# SYSCTRL_PADCONF_CORE register map
Vendor: Texas Instruments
Registers are 32-bit, access per field, reset 0x10F010F unless marked. A register's access mark holds for its fields unless they carry their own. Offsets are as the file gives them; [hi:lo] are bit positions; 'fields as' and 'values as' point back to an identical list.

## SYSCTRL_PADCONF_CORE (part 2 of 10)
0x00 CONTROL_PADCONF_CORE_REVISION ro reset not defined — Control module revision identifier Access conditions. Read: unrestricted, Write: unrestricted
  [31:0] REVISION — IP Revision
0x04 CONTROL_PADCONF_CORE_HWINFO ro reset 0x0 — Information about the IP module hardware configuration that is, typically the module HDL generics (if any). Access conditions. Read: unrestricted, Write: unrestricted
  [31:0] IP_HWINFO — IP-module dependent
0x10 CONTROL_PADCONF_CORE_SYSCONFIG reset 0x8 — Access conditions. Read: unrestricted, Write: unrestricted
  [3:2] IP_SYSCONFIG_IDLEMODE rw — Select the local clock-gating strategy0x2,0x3: Clock is automatically gated when there is no access to the Control Module through L4-interconnect .
    0=Clock is manually gated; 1=Clock is manually enabled
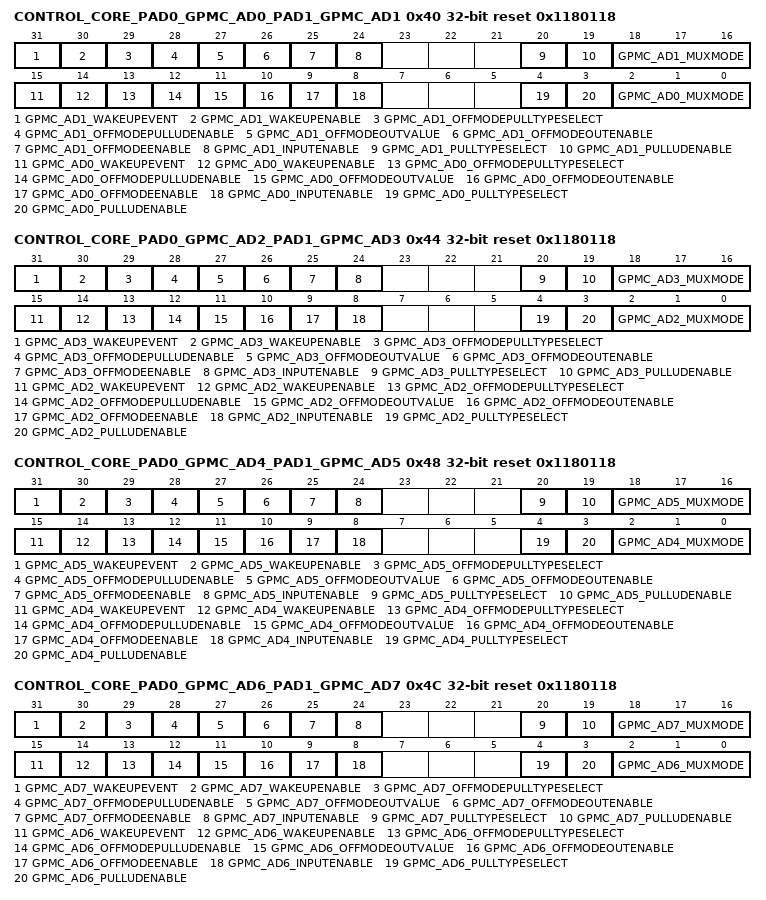
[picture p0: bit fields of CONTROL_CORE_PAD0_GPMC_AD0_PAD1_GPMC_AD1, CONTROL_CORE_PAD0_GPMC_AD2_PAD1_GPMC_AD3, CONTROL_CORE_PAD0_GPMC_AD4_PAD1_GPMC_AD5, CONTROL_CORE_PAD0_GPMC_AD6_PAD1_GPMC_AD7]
0x40 CONTROL_CORE_PAD0_GPMC_AD0_PAD1_GPMC_AD1 reset 0x1180118 — Register control for Pads gpmc_ad0 and gpmc_ad1 Access conditions. Read: unrestricted, Write: unrestricted
  [31] GPMC_AD1_WAKEUPEVENT ro — Pad_x wake-up event status latched in the I/O
    0=GPMC_AD1_WAKEUPEVENT_0_r (No wake-up event occurred); 1=GPMC_AD1_WAKEUPEVENT_1_r (A wake-up event occurred)
  [30] GPMC_AD1_WAKEUPENABLE rw — Input pad wake-up enable (and OFF mode input enable value)
    0=wake-up detection is disabled; 1=wake-up detection is enabled
  [29] GPMC_AD1_OFFMODEPULLTYPESELECT rw — OffMode mode pullup/down selection for pad gpmc_ad1
    0=Offmode pulldown selected; 1=Offmode pullup selected
  [28] GPMC_AD1_OFFMODEPULLUDENABLE rw — OffMode mode pullup/down enable for pad gpmc_ad1
    0=Offmode pullup/down disabled; 1=Offmode pullup/down enabled
  [27] GPMC_AD1_OFFMODEOUTVALUE rw — OffMode mode output value for pad gpmc_ad1
    0=Set value at 0; 1=Set value at 1
  [26] GPMC_AD1_OFFMODEOUTENABLE rw — OffMode mode output enable value for pad gpmc_ad1. This is an active low signal
    0=Output enable; 1=Output disable
  [25] GPMC_AD1_OFFMODEENABLE rw — OffMode mode override control for pad gpmc_ad1
    0=I/O state keeps its previous state when OFF mode is active; 1=I/O state is forced to OFF mode value when OFF mode is active
  [24] GPMC_AD1_INPUTENABLE rw — Input enable value for pad gpmc_ad1
    0=Input buffer of I/O cell is disabled; 1=Input buffer of I/O cell is enabled
  [20] GPMC_AD1_PULLTYPESELECT rw — pullup/down selection for pad gpmc_ad1
    0=pulldown selected; 1=pullup selected
  [19] GPMC_AD1_PULLUDENABLE rw — pullup/down enable for pad gpmc_ad1
    0=pullup/down disabled; 1=pullup/down enabled
  [18:16] GPMC_AD1_MUXMODE rw — Functional multiplexing selection for pad gpmc_ad1
    0=Select gpmc_ad1; 1=Select sdmmc2_dat1
  [15] GPMC_AD0_WAKEUPEVENT ro — Pad_x wake-up event status latched in the IO
    0=GPMC_AD0_WAKEUPEVENT_0_r (No wake-up event occurred); 1=GPMC_AD0_WAKEUPEVENT_1_r (A wake-up event occurred)
  [14] GPMC_AD0_WAKEUPENABLE rw — Input pad wake-up enable (and OFF mode input enable value)
    values as GPMC_AD1_WAKEUPENABLE
  [13] GPMC_AD0_OFFMODEPULLTYPESELECT rw — OffMode mode pullup/down selection for pad gpmc_ad0
    0=Offmode pulldown selected; 1=Offmode pullup selected
  [12] GPMC_AD0_OFFMODEPULLUDENABLE rw — OffMode mode pullup/down enable for pad gpmc_ad0
    values as GPMC_AD1_OFFMODEPULLUDENABLE
  [11] GPMC_AD0_OFFMODEOUTVALUE rw — OffMode mode output value for pad gpmc_ad0
    0=Set value at 0; 1=Set value at 1
  [10] GPMC_AD0_OFFMODEOUTENABLE rw — OffMode mode output enable value for pad gpmc_ad0. This is an active low signal
    0=Output enable; 1=Output disable
  [9] GPMC_AD0_OFFMODEENABLE rw — OffMode mode override control for pad gpmc_ad0
    values as GPMC_AD1_OFFMODEENABLE
  [8] GPMC_AD0_INPUTENABLE rw — Input enable value for pad gpmc_ad0
    values as GPMC_AD1_INPUTENABLE
  [4] GPMC_AD0_PULLTYPESELECT rw — pullup/down selection for pad gpmc_ad0
    0=pulldown selected; 1=pullup selected
  [3] GPMC_AD0_PULLUDENABLE rw — pullup/down enable for pad gpmc_ad0
    0=pullup/down disabled; 1=pullup/down enabled
  [2:0] GPMC_AD0_MUXMODE rw — Functional multiplexing selection for pad gpmc_ad0
    0=Select gpmc_ad0; 1=Select sdmmc2_dat0
0x44 CONTROL_CORE_PAD0_GPMC_AD2_PAD1_GPMC_AD3 reset 0x1180118 — Register control for Pads gpmc_ad2 and gpmc_ad3 Access conditions. Read: unrestricted, Write: unrestricted
  [31] GPMC_AD3_WAKEUPEVENT ro — Pad_x wake-up event status latched in the IO
    0=GPMC_AD3_WAKEUPEVENT_0_r (No wake-up event occurred); 1=GPMC_AD3_WAKEUPEVENT_1_r (A wake-up event occurred)
  [30] GPMC_AD3_WAKEUPENABLE rw — Input pad wake-up enable (and OFF mode input enable value)
    values as CONTROL_CORE_PAD0_GPMC_AD0_PAD1_GPMC_AD1.GPMC_AD1_WAKEUPENABLE
  [29] GPMC_AD3_OFFMODEPULLTYPESELECT rw — OffMode mode pullup/down selection for pad gpmc_ad3
    0=Offmode pulldown selected; 1=Offmode pullup selected
  [28] GPMC_AD3_OFFMODEPULLUDENABLE rw — OffMode mode pullup/down enable for pad gpmc_ad3
    values as CONTROL_CORE_PAD0_GPMC_AD0_PAD1_GPMC_AD1.GPMC_AD1_OFFMODEPULLUDENABLE
  [27] GPMC_AD3_OFFMODEOUTVALUE rw — OffMode mode output value for pad gpmc_ad3
    0=Set value at 0; 1=Set value at 1
  [26] GPMC_AD3_OFFMODEOUTENABLE rw — OffMode mode output enable value for pad gpmc_ad3. This is an active low signal
    0=Output enable; 1=Output disable
  [25] GPMC_AD3_OFFMODEENABLE rw — OffMode mode override control for pad gpmc_ad3
    values as CONTROL_CORE_PAD0_GPMC_AD0_PAD1_GPMC_AD1.GPMC_AD1_OFFMODEENABLE
  [24] GPMC_AD3_INPUTENABLE rw — Input enable value for pad gpmc_ad3
    values as CONTROL_CORE_PAD0_GPMC_AD0_PAD1_GPMC_AD1.GPMC_AD1_INPUTENABLE
  [20] GPMC_AD3_PULLTYPESELECT rw — pullup/down selection for pad gpmc_ad3
    0=pulldown selected; 1=pullup selected
  [19] GPMC_AD3_PULLUDENABLE rw — pullup/down enable for pad gpmc_ad3
    0=pullup/down disabled; 1=pullup/down enabled
  [18:16] GPMC_AD3_MUXMODE rw — Functional multiplexing selection for pad gpmc_ad3
    0=Select gpmc_ad3; 1=Select sdmmc2_dat3
  [15] GPMC_AD2_WAKEUPEVENT ro — Pad_x wake-up event status latched in the IO
    0=GPMC_AD2_WAKEUPEVENT_0_r (No wake-up event occurred); 1=GPMC_AD2_WAKEUPEVENT_1_r (A wake-up event occurred)
  [14] GPMC_AD2_WAKEUPENABLE rw — Input pad wake-up enable (and OFF mode input enable value)
    values as CONTROL_CORE_PAD0_GPMC_AD0_PAD1_GPMC_AD1.GPMC_AD1_WAKEUPENABLE
  [13] GPMC_AD2_OFFMODEPULLTYPESELECT rw — OffMode mode pullup/down selection for pad gpmc_ad2
    0=Offmode pulldown selected; 1=Offmode pullup selected
  [12] GPMC_AD2_OFFMODEPULLUDENABLE rw — OffMode mode pullup/down enable for pad gpmc_ad2
    values as CONTROL_CORE_PAD0_GPMC_AD0_PAD1_GPMC_AD1.GPMC_AD1_OFFMODEPULLUDENABLE
  [11] GPMC_AD2_OFFMODEOUTVALUE rw — OffMode mode output value for pad gpmc_ad2
    0=Set value at 0; 1=Set value at 1
  [10] GPMC_AD2_OFFMODEOUTENABLE rw — OffMode mode output enable value for pad gpmc_ad2. This is an active low signal
    0=Output enable; 1=Output disable
  [9] GPMC_AD2_OFFMODEENABLE rw — OffMode mode override control for pad gpmc_ad2
    values as CONTROL_CORE_PAD0_GPMC_AD0_PAD1_GPMC_AD1.GPMC_AD1_OFFMODEENABLE
  [8] GPMC_AD2_INPUTENABLE rw — Input enable value for pad gpmc_ad2
    values as CONTROL_CORE_PAD0_GPMC_AD0_PAD1_GPMC_AD1.GPMC_AD1_INPUTENABLE
  [4] GPMC_AD2_PULLTYPESELECT rw — pullup/down selection for pad gpmc_ad2
    0=pulldown selected; 1=pullup selected
  [3] GPMC_AD2_PULLUDENABLE rw — pullup/down enable for pad gpmc_ad2
    0=pullup/down disabled; 1=pullup/down enabled
  [2:0] GPMC_AD2_MUXMODE rw — Functional multiplexing selection for pad gpmc_ad2
    0=Select gpmc_ad2; 1=Select sdmmc2_dat2
0x48 CONTROL_CORE_PAD0_GPMC_AD4_PAD1_GPMC_AD5 reset 0x1180118 — Register control for Pads gpmc_ad4 and gpmc_ad5 Access conditions. Read: unrestricted, Write: unrestricted
  [31] GPMC_AD5_WAKEUPEVENT ro — Pad_x wake-up event status latched in the IO
    0=GPMC_AD5_WAKEUPEVENT_0_r (No wake-up event occurred); 1=GPMC_AD5_WAKEUPEVENT_1_r (A wake-up event occurred)
  [30] GPMC_AD5_WAKEUPENABLE rw — Input pad wake-up enable (and OFF mode input enable value)
    values as CONTROL_CORE_PAD0_GPMC_AD0_PAD1_GPMC_AD1.GPMC_AD1_WAKEUPENABLE
  [29] GPMC_AD5_OFFMODEPULLTYPESELECT rw — OffMode mode pullup/down selection for pad gpmc_ad5
    0=Offmode pulldown selected; 1=Offmode pullup selected
  [28] GPMC_AD5_OFFMODEPULLUDENABLE rw — OffMode mode pullup/down enable for pad gpmc_ad5
    values as CONTROL_CORE_PAD0_GPMC_AD0_PAD1_GPMC_AD1.GPMC_AD1_OFFMODEPULLUDENABLE
  [27] GPMC_AD5_OFFMODEOUTVALUE rw — OffMode mode output value for pad gpmc_ad5
    0=Set value at 0; 1=Set value at 1
  [26] GPMC_AD5_OFFMODEOUTENABLE rw — OffMode mode output enable value for pad gpmc_ad5. This is an active low signal
    0=Output enable; 1=Output disable
  [25] GPMC_AD5_OFFMODEENABLE rw — OffMode mode override control for pad gpmc_ad5
    values as CONTROL_CORE_PAD0_GPMC_AD0_PAD1_GPMC_AD1.GPMC_AD1_OFFMODEENABLE
  [24] GPMC_AD5_INPUTENABLE rw — Input enable value for pad gpmc_ad5
    values as CONTROL_CORE_PAD0_GPMC_AD0_PAD1_GPMC_AD1.GPMC_AD1_INPUTENABLE
  [20] GPMC_AD5_PULLTYPESELECT rw — pullup/down selection for pad gpmc_ad5
    0=pulldown selected; 1=pullup selected
  [19] GPMC_AD5_PULLUDENABLE rw — pullup/down enable for pad gpmc_ad5
    0=pullup/down disabled; 1=pullup/down enabled
  [18:16] GPMC_AD5_MUXMODE rw — Functional multiplexing selection for pad gpmc_ad5
    0=Select gpmc_ad5; 1=Select sdmmc2_dat5; 2=Select sdmmc2_dir_dat1
  [15] GPMC_AD4_WAKEUPEVENT ro — Pad_x wake-up event status latched in the IO
    0=GPMC_AD4_WAKEUPEVENT_0_r (No wake-up event occurred); 1=GPMC_AD4_WAKEUPEVENT_1_r (A wake-up event occurred)
  [14] GPMC_AD4_WAKEUPENABLE rw — Input pad wake-up enable (and OFF mode input enable value)
    values as CONTROL_CORE_PAD0_GPMC_AD0_PAD1_GPMC_AD1.GPMC_AD1_WAKEUPENABLE
  [13] GPMC_AD4_OFFMODEPULLTYPESELECT rw — OffMode mode pullup/down selection for pad gpmc_ad4
    0=Offmode pulldown selected; 1=Offmode pullup selected
  [12] GPMC_AD4_OFFMODEPULLUDENABLE rw — OffMode mode pullup/down enable for pad gpmc_ad4
    values as CONTROL_CORE_PAD0_GPMC_AD0_PAD1_GPMC_AD1.GPMC_AD1_OFFMODEPULLUDENABLE
  [11] GPMC_AD4_OFFMODEOUTVALUE rw — OffMode mode output value for pad gpmc_ad4
    0=Set value at 0; 1=Set value at 1
  [10] GPMC_AD4_OFFMODEOUTENABLE rw — OffMode mode output enable value for pad gpmc_ad4. This is an active low signal
    0=Output enable; 1=Output disable
  [9] GPMC_AD4_OFFMODEENABLE rw — OffMode mode override control for pad gpmc_ad4
    values as CONTROL_CORE_PAD0_GPMC_AD0_PAD1_GPMC_AD1.GPMC_AD1_OFFMODEENABLE
  [8] GPMC_AD4_INPUTENABLE rw — Input enable value for pad gpmc_ad4
    values as CONTROL_CORE_PAD0_GPMC_AD0_PAD1_GPMC_AD1.GPMC_AD1_INPUTENABLE
  [4] GPMC_AD4_PULLTYPESELECT rw — pullup/down selection for pad gpmc_ad4
    0=pulldown selected; 1=pullup selected
  [3] GPMC_AD4_PULLUDENABLE rw — pullup/down enable for pad gpmc_ad4
    0=pullup/down disabled; 1=pullup/down enabled
  [2:0] GPMC_AD4_MUXMODE rw — Functional multiplexing selection for pad gpmc_ad4
    0=Select gpmc_ad4; 1=Select sdmmc2_dat4; 2=Select sdmmc2_dir_dat0
0x4C CONTROL_CORE_PAD0_GPMC_AD6_PAD1_GPMC_AD7 reset 0x1180118 — Register control for Pads gpmc_ad6 and gpmc_ad7 Access conditions. Read: unrestricted, Write: unrestricted
  [31] GPMC_AD7_WAKEUPEVENT ro — Pad_x wake-up event status latched in the IO
    0=GPMC_AD7_WAKEUPEVENT_0_r (No wake-up event occurred); 1=GPMC_AD7_WAKEUPEVENT_1_r (A wake-up event occurred)
  [30] GPMC_AD7_WAKEUPENABLE rw — Input pad wake-up enable (and OFF mode input enable value)
    values as CONTROL_CORE_PAD0_GPMC_AD0_PAD1_GPMC_AD1.GPMC_AD1_WAKEUPENABLE
  [29] GPMC_AD7_OFFMODEPULLTYPESELECT rw — OffMode mode pullup/down selection for pad gpmc_ad7
    0=Offmode pulldown selected; 1=Offmode pullup selected
  [28] GPMC_AD7_OFFMODEPULLUDENABLE rw — OffMode mode pullup/down enable for pad gpmc_ad7
    values as CONTROL_CORE_PAD0_GPMC_AD0_PAD1_GPMC_AD1.GPMC_AD1_OFFMODEPULLUDENABLE
  [27] GPMC_AD7_OFFMODEOUTVALUE rw — OffMode mode output value for pad gpmc_ad7
    0=Set value at 0; 1=Set value at 1
  [26] GPMC_AD7_OFFMODEOUTENABLE rw — OffMode mode output enable value for pad gpmc_ad7. This is an active low signal
    0=Output enable; 1=Output disable
  [25] GPMC_AD7_OFFMODEENABLE rw — OffMode mode override control for pad gpmc_ad7
    values as CONTROL_CORE_PAD0_GPMC_AD0_PAD1_GPMC_AD1.GPMC_AD1_OFFMODEENABLE
  [24] GPMC_AD7_INPUTENABLE rw — Input enable value for pad gpmc_ad7
    values as CONTROL_CORE_PAD0_GPMC_AD0_PAD1_GPMC_AD1.GPMC_AD1_INPUTENABLE
  [20] GPMC_AD7_PULLTYPESELECT rw — pullup/down selection for pad gpmc_ad7
    0=pulldown selected; 1=pullup selected
  [19] GPMC_AD7_PULLUDENABLE rw — pullup/down enable for pad gpmc_ad7
    0=pullup/down disabled; 1=pullup/down enabled
  [18:16] GPMC_AD7_MUXMODE rw — Functional multiplexing selection for pad gpmc_ad7
    0=Select gpmc_ad7; 1=Select sdmmc2_dat7; 2=Select sdmmc2_clk_fdbk
  [15] GPMC_AD6_WAKEUPEVENT ro — Pad_x wake-up event status latched in the IO
    0=GPMC_AD6_WAKEUPEVENT_0_r (No wake-up event occurred); 1=GPMC_AD6_WAKEUPEVENT_1_r (A wake-up event occurred)
  [14] GPMC_AD6_WAKEUPENABLE rw — Input pad wake-up enable (and OFF mode input enable value)
    values as CONTROL_CORE_PAD0_GPMC_AD0_PAD1_GPMC_AD1.GPMC_AD1_WAKEUPENABLE
  [13] GPMC_AD6_OFFMODEPULLTYPESELECT rw — OffMode mode pullup/down selection for pad gpmc_ad6
    0=Offmode pulldown selected; 1=Offmode pullup selected
  [12] GPMC_AD6_OFFMODEPULLUDENABLE rw — OffMode mode pullup/down enable for pad gpmc_ad6
    values as CONTROL_CORE_PAD0_GPMC_AD0_PAD1_GPMC_AD1.GPMC_AD1_OFFMODEPULLUDENABLE
  [11] GPMC_AD6_OFFMODEOUTVALUE rw — OffMode mode output value for pad gpmc_ad6
    0=Set value at 0; 1=Set value at 1
  [10] GPMC_AD6_OFFMODEOUTENABLE rw — OffMode mode output enable value for pad gpmc_ad6. This is an active low signal
    0=Output enable; 1=Output disable
  [9] GPMC_AD6_OFFMODEENABLE rw — OffMode mode override control for pad gpmc_ad6
    values as CONTROL_CORE_PAD0_GPMC_AD0_PAD1_GPMC_AD1.GPMC_AD1_OFFMODEENABLE
  [8] GPMC_AD6_INPUTENABLE rw — Input enable value for pad gpmc_ad6
    values as CONTROL_CORE_PAD0_GPMC_AD0_PAD1_GPMC_AD1.GPMC_AD1_INPUTENABLE
  [4] GPMC_AD6_PULLTYPESELECT rw — pullup/down selection for pad gpmc_ad6
    0=pulldown selected; 1=pullup selected
  [3] GPMC_AD6_PULLUDENABLE rw — pullup/down enable for pad gpmc_ad6
    0=pullup/down disabled; 1=pullup/down enabled
  [2:0] GPMC_AD6_MUXMODE rw — Functional multiplexing selection for pad gpmc_ad6
    0=Select gpmc_ad6; 1=Select sdmmc2_dat6; 2=Select sdmmc2_dir_cmd
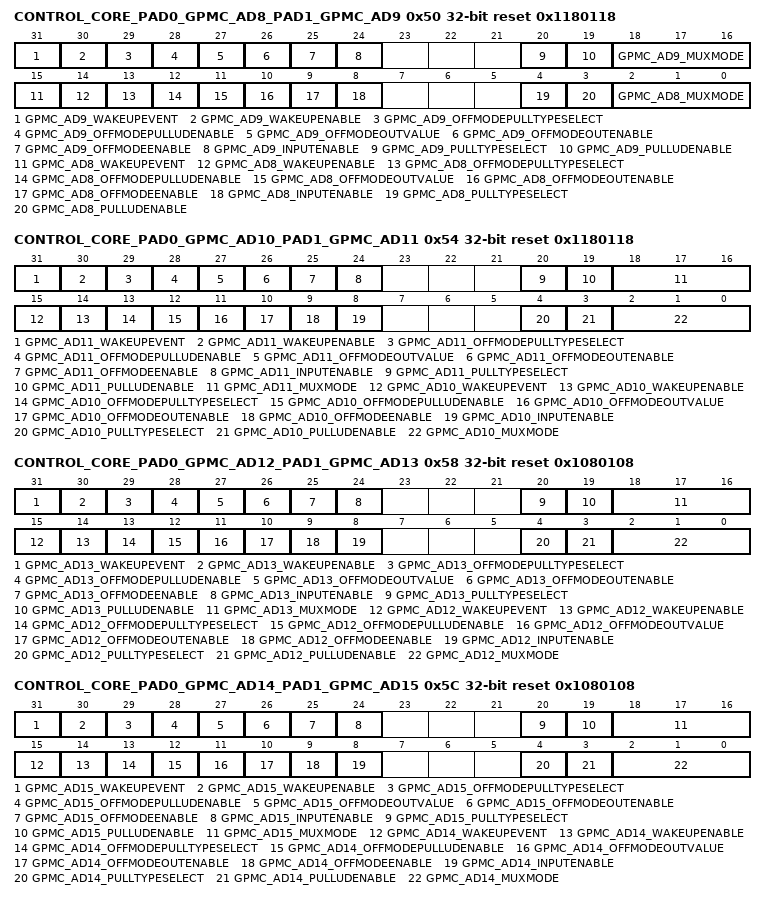
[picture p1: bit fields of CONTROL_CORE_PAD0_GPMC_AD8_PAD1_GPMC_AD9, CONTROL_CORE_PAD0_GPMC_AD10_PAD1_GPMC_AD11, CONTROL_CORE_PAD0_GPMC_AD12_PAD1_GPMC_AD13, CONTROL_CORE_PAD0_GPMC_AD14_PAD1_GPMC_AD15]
0x50 CONTROL_CORE_PAD0_GPMC_AD8_PAD1_GPMC_AD9 reset 0x1180118 — Register control for Pads gpmc_ad8 and gpmc_ad9 Access conditions. Read: unrestricted, Write: unrestricted
  [31] GPMC_AD9_WAKEUPEVENT ro — Pad_x wake-up event status latched in the IO
    0=GPMC_AD9_WAKEUPEVENT_0_r (No wake-up event occurred); 1=GPMC_AD9_WAKEUPEVENT_1_r (A wake-up event occurred)
  [30] GPMC_AD9_WAKEUPENABLE rw — Input pad wake-up enable (and OFF mode input enable value)
    values as CONTROL_CORE_PAD0_GPMC_AD0_PAD1_GPMC_AD1.GPMC_AD1_WAKEUPENABLE
  [29] GPMC_AD9_OFFMODEPULLTYPESELECT rw — OffMode mode pullup/down selection for pad gpmc_ad9
    0=Offmode pulldown selected; 1=Offmode pullup selected
  [28] GPMC_AD9_OFFMODEPULLUDENABLE rw — OffMode mode pullup/down enable for pad gpmc_ad9
    values as CONTROL_CORE_PAD0_GPMC_AD0_PAD1_GPMC_AD1.GPMC_AD1_OFFMODEPULLUDENABLE
  [27] GPMC_AD9_OFFMODEOUTVALUE rw — OffMode mode output value for pad gpmc_ad9
    0=Set value at 0; 1=Set value at 1
  [26] GPMC_AD9_OFFMODEOUTENABLE rw — OffMode mode output enable value for pad gpmc_ad9. This is an active low signal
    0=Output enable; 1=Output disable
  [25] GPMC_AD9_OFFMODEENABLE rw — OffMode mode override control for pad gpmc_ad9
    values as CONTROL_CORE_PAD0_GPMC_AD0_PAD1_GPMC_AD1.GPMC_AD1_OFFMODEENABLE
  [24] GPMC_AD9_INPUTENABLE rw — Input enable value for pad gpmc_ad9
    values as CONTROL_CORE_PAD0_GPMC_AD0_PAD1_GPMC_AD1.GPMC_AD1_INPUTENABLE
  [20] GPMC_AD9_PULLTYPESELECT rw — pullup/down selection for pad gpmc_ad9
    0=pulldown selected; 1=pullup selected
  [19] GPMC_AD9_PULLUDENABLE rw — pullup/down enable for pad gpmc_ad9
    0=pullup/down disabled; 1=pullup/down enabled
  [18:16] GPMC_AD9_MUXMODE rw — Functional multiplexing selection for pad gpmc_ad9
    0=Select gpmc_ad9; 1=Select kpd_row1; 2=Select c2c_data14; 3=Select gpio_33; 5=Select sdmmc1_dat1
  [15] GPMC_AD8_WAKEUPEVENT ro — Pad_x wake-up event status latched in the IO
    0=GPMC_AD8_WAKEUPEVENT_0_r (No wake-up event occurred); 1=GPMC_AD8_WAKEUPEVENT_1_r (A wake-up event occurred)
  [14] GPMC_AD8_WAKEUPENABLE rw — Input pad wake-up enable (and OFF mode input enable value)
    values as CONTROL_CORE_PAD0_GPMC_AD0_PAD1_GPMC_AD1.GPMC_AD1_WAKEUPENABLE
  [13] GPMC_AD8_OFFMODEPULLTYPESELECT rw — OffMode mode pullup/down selection for pad gpmc_ad8
    0=Offmode pulldown selected; 1=Offmode pullup selected
  [12] GPMC_AD8_OFFMODEPULLUDENABLE rw — OffMode mode pullup/down enable for pad gpmc_ad8
    values as CONTROL_CORE_PAD0_GPMC_AD0_PAD1_GPMC_AD1.GPMC_AD1_OFFMODEPULLUDENABLE
  [11] GPMC_AD8_OFFMODEOUTVALUE rw — OffMode mode output value for pad gpmc_ad8
    0=Set value at 0; 1=Set value at 1
  [10] GPMC_AD8_OFFMODEOUTENABLE rw — OffMode mode output enable value for pad gpmc_ad8. This is an active low signal
    0=Output enable; 1=Output disable
  [9] GPMC_AD8_OFFMODEENABLE rw — OffMode mode override control for pad gpmc_ad8
    values as CONTROL_CORE_PAD0_GPMC_AD0_PAD1_GPMC_AD1.GPMC_AD1_OFFMODEENABLE
  [8] GPMC_AD8_INPUTENABLE rw — Input enable value for pad gpmc_ad8
    values as CONTROL_CORE_PAD0_GPMC_AD0_PAD1_GPMC_AD1.GPMC_AD1_INPUTENABLE
  [4] GPMC_AD8_PULLTYPESELECT rw — pullup/down selection for pad gpmc_ad8
    0=pulldown selected; 1=pullup selected
  [3] GPMC_AD8_PULLUDENABLE rw — pullup/down enable for pad gpmc_ad8
    0=pullup/down disabled; 1=pullup/down enabled
  [2:0] GPMC_AD8_MUXMODE rw — Functional multiplexing selection for pad gpmc_ad8
    0=Select gpmc_ad8; 1=Select kpd_row0; 2=Select c2c_data15; 3=Select gpio_32; 5=Select sdmmc1_dat0
0x54 CONTROL_CORE_PAD0_GPMC_AD10_PAD1_GPMC_AD11 reset 0x1180118 — Register control for Pads gpmc_ad10 and gpmc_ad11 Access conditions. Read: unrestricted, Write: unrestricted
  [31] GPMC_AD11_WAKEUPEVENT ro — Pad_x wake-up event status latched in the IO
    0=GPMC_AD11_WAKEUPEVENT_0_r (No wake-up event occurred); 1=GPMC_AD11_WAKEUPEVENT_1_r (A wake-up event occurred)
  [30] GPMC_AD11_WAKEUPENABLE rw — Input pad wake-up enable (and OFF mode input enable value)
    values as CONTROL_CORE_PAD0_GPMC_AD0_PAD1_GPMC_AD1.GPMC_AD1_WAKEUPENABLE
  [29] GPMC_AD11_OFFMODEPULLTYPESELECT rw — OffMode mode pullup/down selection for pad gpmc_ad11
    0=Offmode pulldown selected; 1=Offmode pullup selected
  [28] GPMC_AD11_OFFMODEPULLUDENABLE rw — OffMode mode pullup/down enable for pad gpmc_ad11
    values as CONTROL_CORE_PAD0_GPMC_AD0_PAD1_GPMC_AD1.GPMC_AD1_OFFMODEPULLUDENABLE
  [27] GPMC_AD11_OFFMODEOUTVALUE rw — OffMode mode output value for pad gpmc_ad11
    0=Set value at 0; 1=Set value at 1
  [26] GPMC_AD11_OFFMODEOUTENABLE rw — OffMode mode output enable value for pad gpmc_ad11. This is an active low signal
    0=Output enable; 1=Output disable
  [25] GPMC_AD11_OFFMODEENABLE rw — OffMode mode override control for pad gpmc_ad11
    values as CONTROL_CORE_PAD0_GPMC_AD0_PAD1_GPMC_AD1.GPMC_AD1_OFFMODEENABLE
  [24] GPMC_AD11_INPUTENABLE rw — Input enable value for pad gpmc_ad11
    values as CONTROL_CORE_PAD0_GPMC_AD0_PAD1_GPMC_AD1.GPMC_AD1_INPUTENABLE
  [20] GPMC_AD11_PULLTYPESELECT rw — pullup/down selection for pad gpmc_ad11
    0=pulldown selected; 1=pullup selected
  [19] GPMC_AD11_PULLUDENABLE rw — pullup/down enable for pad gpmc_ad11
    0=pullup/down disabled; 1=pullup/down enabled
  [18:16] GPMC_AD11_MUXMODE rw — Functional multiplexing selection for pad gpmc_ad11
    0=Select gpmc_ad11; 1=Select kpd_row3; 2=Select c2c_data12; 3=Select gpio_35; 5=Select sdmmc1_dat3
  [15] GPMC_AD10_WAKEUPEVENT ro — Pad_x wake-up event status latched in the IO
    0=GPMC_AD10_WAKEUPEVENT_0_r (No wake-up event occurred); 1=GPMC_AD10_WAKEUPEVENT_1_r (A wake-up event occurred)
  [14] GPMC_AD10_WAKEUPENABLE rw — Input pad wake-up enable (and OFF mode input enable value)
    values as CONTROL_CORE_PAD0_GPMC_AD0_PAD1_GPMC_AD1.GPMC_AD1_WAKEUPENABLE
  [13] GPMC_AD10_OFFMODEPULLTYPESELECT rw — OffMode mode pullup/down selection for pad gpmc_ad10
    0=Offmode pulldown selected; 1=Offmode pullup selected
  [12] GPMC_AD10_OFFMODEPULLUDENABLE rw — OffMode mode pullup/down enable for pad gpmc_ad10
    values as CONTROL_CORE_PAD0_GPMC_AD0_PAD1_GPMC_AD1.GPMC_AD1_OFFMODEPULLUDENABLE
  [11] GPMC_AD10_OFFMODEOUTVALUE rw — OffMode mode output value for pad gpmc_ad10
    0=Set value at 0; 1=Set value at 1
  [10] GPMC_AD10_OFFMODEOUTENABLE rw — OffMode mode output enable value for pad gpmc_ad10. This is an active low signal
    0=Output enable; 1=Output disable
  [9] GPMC_AD10_OFFMODEENABLE rw — OffMode mode override control for pad gpmc_ad10
    values as CONTROL_CORE_PAD0_GPMC_AD0_PAD1_GPMC_AD1.GPMC_AD1_OFFMODEENABLE
  [8] GPMC_AD10_INPUTENABLE rw — Input enable value for pad gpmc_ad10
    values as CONTROL_CORE_PAD0_GPMC_AD0_PAD1_GPMC_AD1.GPMC_AD1_INPUTENABLE
  [4] GPMC_AD10_PULLTYPESELECT rw — pullup/down selection for pad gpmc_ad10
    0=pulldown selected; 1=pullup selected
  [3] GPMC_AD10_PULLUDENABLE rw — pullup/down enable for pad gpmc_ad10
    0=pullup/down disabled; 1=pullup/down enabled
  [2:0] GPMC_AD10_MUXMODE rw — Functional multiplexing selection for pad gpmc_ad10
    0=Select gpmc_ad10; 1=Select kpd_row2; 2=Select c2c_data13; 3=Select gpio_34; 5=Select sdmmc1_dat2
0x58 CONTROL_CORE_PAD0_GPMC_AD12_PAD1_GPMC_AD13 reset 0x1080108 — Register control for Pads gpmc_ad12 and gpmc_ad13 Access conditions. Read: unrestricted, Write: unrestricted
  [31] GPMC_AD13_WAKEUPEVENT ro — Pad_x wake-up event status latched in the IO
    0=GPMC_AD13_WAKEUPEVENT_0_r (No wake-up event occurred); 1=GPMC_AD13_WAKEUPEVENT_1_r (A wake-up event occurred)
  [30] GPMC_AD13_WAKEUPENABLE rw — Input pad wake-up enable (and OFF mode input enable value)
    values as CONTROL_CORE_PAD0_GPMC_AD0_PAD1_GPMC_AD1.GPMC_AD1_WAKEUPENABLE
  [29] GPMC_AD13_OFFMODEPULLTYPESELECT rw — OffMode mode pullup/down selection for pad gpmc_ad13
    0=Offmode pulldown selected; 1=Offmode pullup selected
  [28] GPMC_AD13_OFFMODEPULLUDENABLE rw — OffMode mode pullup/down enable for pad gpmc_ad13
    values as CONTROL_CORE_PAD0_GPMC_AD0_PAD1_GPMC_AD1.GPMC_AD1_OFFMODEPULLUDENABLE
  [27] GPMC_AD13_OFFMODEOUTVALUE rw — OffMode mode output value for pad gpmc_ad13
    0=Set value at 0; 1=Set value at 1
  [26] GPMC_AD13_OFFMODEOUTENABLE rw — OffMode mode output enable value for pad gpmc_ad13. This is an active low signal
    0=Output enable; 1=Output disable
  [25] GPMC_AD13_OFFMODEENABLE rw — OffMode mode override control for pad gpmc_ad13
    values as CONTROL_CORE_PAD0_GPMC_AD0_PAD1_GPMC_AD1.GPMC_AD1_OFFMODEENABLE
  [24] GPMC_AD13_INPUTENABLE rw — Input enable value for pad gpmc_ad13
    values as CONTROL_CORE_PAD0_GPMC_AD0_PAD1_GPMC_AD1.GPMC_AD1_INPUTENABLE
  [20] GPMC_AD13_PULLTYPESELECT rw — pullup/down selection for pad gpmc_ad13
    0=pulldown selected; 1=pullup selected
  [19] GPMC_AD13_PULLUDENABLE rw — pullup/down enable for pad gpmc_ad13
    0=pullup/down disabled; 1=pullup/down enabled
  [18:16] GPMC_AD13_MUXMODE rw — Functional multiplexing selection for pad gpmc_ad13
    0=Select gpmc_ad13; 1=Select kpd_col1; 2=Select c2c_data10; 3=Select gpio_37; 5=Select sdmmc1_dat5
  [15] GPMC_AD12_WAKEUPEVENT ro — Pad_x wake-up event status latched in the IO
    0=GPMC_AD12_WAKEUPEVENT_0_r (No wake-up event occurred); 1=GPMC_AD12_WAKEUPEVENT_1_r (A wake-up event occurred)
  [14] GPMC_AD12_WAKEUPENABLE rw — Input pad wake-up enable (and OFF mode input enable value)
    values as CONTROL_CORE_PAD0_GPMC_AD0_PAD1_GPMC_AD1.GPMC_AD1_WAKEUPENABLE
  [13] GPMC_AD12_OFFMODEPULLTYPESELECT rw — OffMode mode pullup/down selection for pad gpmc_ad12
    0=Offmode pulldown selected; 1=Offmode pullup selected
  [12] GPMC_AD12_OFFMODEPULLUDENABLE rw — OffMode mode pullup/down enable for pad gpmc_ad12
    values as CONTROL_CORE_PAD0_GPMC_AD0_PAD1_GPMC_AD1.GPMC_AD1_OFFMODEPULLUDENABLE
  [11] GPMC_AD12_OFFMODEOUTVALUE rw — OffMode mode output value for pad gpmc_ad12
    0=Set value at 0; 1=Set value at 1
  [10] GPMC_AD12_OFFMODEOUTENABLE rw — OffMode mode output enable value for pad gpmc_ad12. This is an active low signal
    0=Output enable; 1=Output disable
  [9] GPMC_AD12_OFFMODEENABLE rw — OffMode mode override control for pad gpmc_ad12
    values as CONTROL_CORE_PAD0_GPMC_AD0_PAD1_GPMC_AD1.GPMC_AD1_OFFMODEENABLE
  [8] GPMC_AD12_INPUTENABLE rw — Input enable value for pad gpmc_ad12
    values as CONTROL_CORE_PAD0_GPMC_AD0_PAD1_GPMC_AD1.GPMC_AD1_INPUTENABLE
  [4] GPMC_AD12_PULLTYPESELECT rw — pullup/down selection for pad gpmc_ad12
    0=pulldown selected; 1=pullup selected
  [3] GPMC_AD12_PULLUDENABLE rw — pullup/down enable for pad gpmc_ad12
    0=pullup/down disabled; 1=pullup/down enabled
  [2:0] GPMC_AD12_MUXMODE rw — Functional multiplexing selection for pad gpmc_ad12
    0=Select gpmc_ad12; 1=Select kpd_col0; 2=Select c2c_data11; 3=Select gpio_36; 5=Select sdmmc1_dat4
0x5C CONTROL_CORE_PAD0_GPMC_AD14_PAD1_GPMC_AD15 reset 0x1080108 — Register control for Pads gpmc_ad14 and gpmc_ad15 Access conditions. Read: unrestricted, Write: unrestricted
  [31] GPMC_AD15_WAKEUPEVENT ro — Pad_x wake-up event status latched in the IO
    0=GPMC_AD15_WAKEUPEVENT_0_r (No wake-up event occurred); 1=GPMC_AD15_WAKEUPEVENT_1_r (A wake-up event occurred)
  [30] GPMC_AD15_WAKEUPENABLE rw — Input pad wake-up enable (and OFF mode input enable value)
    values as CONTROL_CORE_PAD0_GPMC_AD0_PAD1_GPMC_AD1.GPMC_AD1_WAKEUPENABLE
  [29] GPMC_AD15_OFFMODEPULLTYPESELECT rw — OffMode mode pullup/down selection for pad gpmc_ad15
    0=Offmode pulldown selected; 1=Offmode pullup selected
  [28] GPMC_AD15_OFFMODEPULLUDENABLE rw — OffMode mode pullup/down enable for pad gpmc_ad15
    values as CONTROL_CORE_PAD0_GPMC_AD0_PAD1_GPMC_AD1.GPMC_AD1_OFFMODEPULLUDENABLE
  [27] GPMC_AD15_OFFMODEOUTVALUE rw — OffMode mode output value for pad gpmc_ad15
    0=Set value at 0; 1=Set value at 1
  [26] GPMC_AD15_OFFMODEOUTENABLE rw — OffMode mode output enable value for pad gpmc_ad15. This is an active low signal
    0=Output enable; 1=Output disable
  [25] GPMC_AD15_OFFMODEENABLE rw — OffMode mode override control for pad gpmc_ad15
    values as CONTROL_CORE_PAD0_GPMC_AD0_PAD1_GPMC_AD1.GPMC_AD1_OFFMODEENABLE
  [24] GPMC_AD15_INPUTENABLE rw — Input enable value for pad gpmc_ad15
    values as CONTROL_CORE_PAD0_GPMC_AD0_PAD1_GPMC_AD1.GPMC_AD1_INPUTENABLE
  [20] GPMC_AD15_PULLTYPESELECT rw — pullup/down selection for pad gpmc_ad15
    0=pulldown selected; 1=pullup selected
  [19] GPMC_AD15_PULLUDENABLE rw — pullup/down enable for pad gpmc_ad15
    0=pullup/down disabled; 1=pullup/down enabled
  [18:16] GPMC_AD15_MUXMODE rw — Functional multiplexing selection for pad gpmc_ad15
    0=Select gpmc_ad15; 1=Select kpd_col3; 2=Select c2c_data8; 3=Select gpio_39; 5=Select sdmmc1_dat7
  [15] GPMC_AD14_WAKEUPEVENT ro — Pad_x wake-up event status latched in the IO
    0=GPMC_AD14_WAKEUPEVENT_0_r (No wake-up event occurred); 1=GPMC_AD14_WAKEUPEVENT_1_r (A wake-up event occurred)
  [14] GPMC_AD14_WAKEUPENABLE rw — Input pad wake-up enable (and OFF mode input enable value)
    values as CONTROL_CORE_PAD0_GPMC_AD0_PAD1_GPMC_AD1.GPMC_AD1_WAKEUPENABLE
  [13] GPMC_AD14_OFFMODEPULLTYPESELECT rw — OffMode mode pullup/down selection for pad gpmc_ad14
    0=Offmode pulldown selected; 1=Offmode pullup selected
  [12] GPMC_AD14_OFFMODEPULLUDENABLE rw — OffMode mode pullup/down enable for pad gpmc_ad14
    values as CONTROL_CORE_PAD0_GPMC_AD0_PAD1_GPMC_AD1.GPMC_AD1_OFFMODEPULLUDENABLE
  [11] GPMC_AD14_OFFMODEOUTVALUE rw — OffMode mode output value for pad gpmc_ad14
    0=Set value at 0; 1=Set value at 1
  [10] GPMC_AD14_OFFMODEOUTENABLE rw — OffMode mode output enable value for pad gpmc_ad14. This is an active low signal
    0=Output enable; 1=Output disable
  [9] GPMC_AD14_OFFMODEENABLE rw — OffMode mode override control for pad gpmc_ad14
    values as CONTROL_CORE_PAD0_GPMC_AD0_PAD1_GPMC_AD1.GPMC_AD1_OFFMODEENABLE
  [8] GPMC_AD14_INPUTENABLE rw — Input enable value for pad gpmc_ad14
    values as CONTROL_CORE_PAD0_GPMC_AD0_PAD1_GPMC_AD1.GPMC_AD1_INPUTENABLE
  [4] GPMC_AD14_PULLTYPESELECT rw — pullup/down selection for pad gpmc_ad14
    0=pulldown selected; 1=pullup selected
  [3] GPMC_AD14_PULLUDENABLE rw — pullup/down enable for pad gpmc_ad14
    0=pullup/down disabled; 1=pullup/down enabled
  [2:0] GPMC_AD14_MUXMODE rw — Functional multiplexing selection for pad gpmc_ad14
    0=Select gpmc_ad14; 1=Select kpd_col2; 2=Select c2c_data9; 3=Select gpio_38; 5=Select sdmmc1_dat6
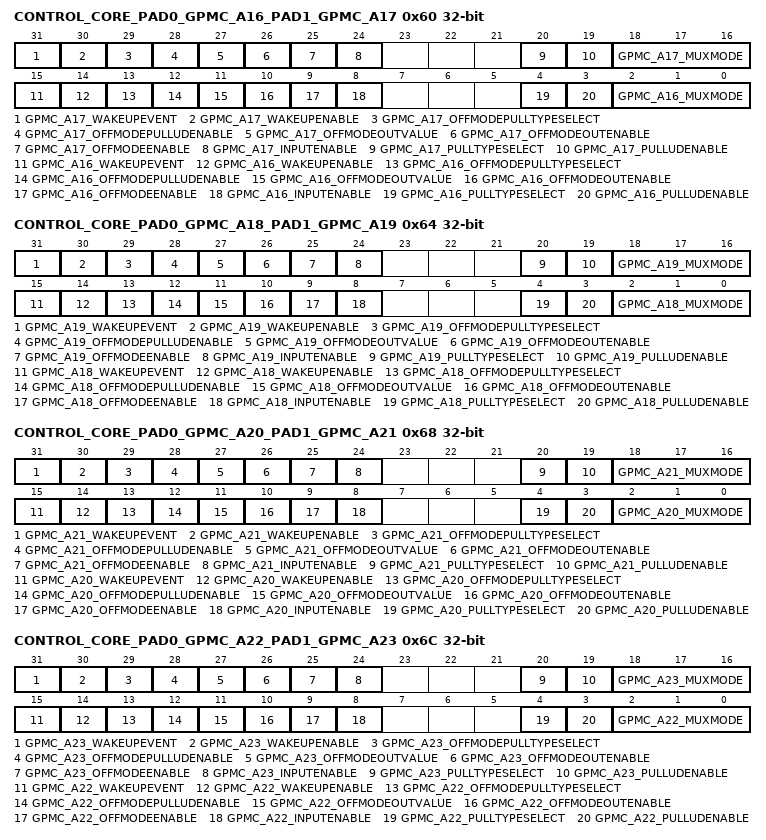
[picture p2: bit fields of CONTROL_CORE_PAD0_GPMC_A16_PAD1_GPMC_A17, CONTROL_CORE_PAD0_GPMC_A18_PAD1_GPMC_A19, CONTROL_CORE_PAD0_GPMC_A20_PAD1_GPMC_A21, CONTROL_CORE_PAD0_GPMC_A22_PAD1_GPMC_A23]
0x60 CONTROL_CORE_PAD0_GPMC_A16_PAD1_GPMC_A17 — Register control for Pads gpmc_a16 and gpmc_a17 Access conditions. Read: unrestricted, Write: unrestricted
  [31] GPMC_A17_WAKEUPEVENT ro — Pad_x wake-up event status latched in the IO
    0=GPMC_A17_WAKEUPEVENT_0_r (No wake-up event occurred); 1=GPMC_A17_WAKEUPEVENT_1_r (A wake-up event occurred)
  [30] GPMC_A17_WAKEUPENABLE rw — Input pad wake-up enable (and OFF mode input enable value)
    values as CONTROL_CORE_PAD0_GPMC_AD0_PAD1_GPMC_AD1.GPMC_AD1_WAKEUPENABLE
  [29] GPMC_A17_OFFMODEPULLTYPESELECT rw — OffMode mode pullup/down selection for pad gpmc_a17
    0=Offmode pulldown selected; 1=Offmode pullup selected
  [28] GPMC_A17_OFFMODEPULLUDENABLE rw — OffMode mode pullup/down enable for pad gpmc_a17
    values as CONTROL_CORE_PAD0_GPMC_AD0_PAD1_GPMC_AD1.GPMC_AD1_OFFMODEPULLUDENABLE
  [27] GPMC_A17_OFFMODEOUTVALUE rw — OffMode mode output value for pad gpmc_a17
    0=Set value at 0; 1=Set value at 1
  [26] GPMC_A17_OFFMODEOUTENABLE rw — OffMode mode output enable value for pad gpmc_a17. This is an active low signal
    0=Output enable; 1=Output disable
  [25] GPMC_A17_OFFMODEENABLE rw — OffMode mode override control for pad gpmc_a17
    values as CONTROL_CORE_PAD0_GPMC_AD0_PAD1_GPMC_AD1.GPMC_AD1_OFFMODEENABLE
  [24] GPMC_A17_INPUTENABLE rw — Input enable value for pad gpmc_a17
    values as CONTROL_CORE_PAD0_GPMC_AD0_PAD1_GPMC_AD1.GPMC_AD1_INPUTENABLE
  [20] GPMC_A17_PULLTYPESELECT rw — pullup/down selection for pad gpmc_a17
    0=pulldown selected; 1=pullup selected
  [19] GPMC_A17_PULLUDENABLE rw — pullup/down enable for pad gpmc_a17
    0=pullup/down disabled; 1=pullup/down enabled
  [18:16] GPMC_A17_MUXMODE rw — Functional multiplexing selection for pad gpmc_a17
    0=Select gpmc_a17; 1=Select kpd_row5; 2=Select c2c_datain1; 3=Select gpio_41; 4=Select venc_656_data1; 7=Select safe_mode
  [15] GPMC_A16_WAKEUPEVENT ro — Pad_x wake-up event status latched in the IO
    0=GPMC_A16_WAKEUPEVENT_0_r (No wake-up event occurred); 1=GPMC_A16_WAKEUPEVENT_1_r (A wake-up event occurred)
  [14] GPMC_A16_WAKEUPENABLE rw — Input pad wake-up enable (and OFF mode input enable value)
    values as CONTROL_CORE_PAD0_GPMC_AD0_PAD1_GPMC_AD1.GPMC_AD1_WAKEUPENABLE
  [13] GPMC_A16_OFFMODEPULLTYPESELECT rw — OffMode mode pullup/down selection for pad gpmc_a16
    0=Offmode pulldown selected; 1=Offmode pullup selected
  [12] GPMC_A16_OFFMODEPULLUDENABLE rw — OffMode mode pullup/down enable for pad gpmc_a16
    values as CONTROL_CORE_PAD0_GPMC_AD0_PAD1_GPMC_AD1.GPMC_AD1_OFFMODEPULLUDENABLE
  [11] GPMC_A16_OFFMODEOUTVALUE rw — OffMode mode output value for pad gpmc_a16
    0=Set value at 0; 1=Set value at 1
  [10] GPMC_A16_OFFMODEOUTENABLE rw — OffMode mode output enable value for pad gpmc_a16. This is an active low signal
    0=Output enable; 1=Output disable
  [9] GPMC_A16_OFFMODEENABLE rw — OffMode mode override control for pad gpmc_a16
    values as CONTROL_CORE_PAD0_GPMC_AD0_PAD1_GPMC_AD1.GPMC_AD1_OFFMODEENABLE
  [8] GPMC_A16_INPUTENABLE rw — Input enable value for pad gpmc_a16
    values as CONTROL_CORE_PAD0_GPMC_AD0_PAD1_GPMC_AD1.GPMC_AD1_INPUTENABLE
  [4] GPMC_A16_PULLTYPESELECT rw — pullup/down selection for pad gpmc_a16
    0=pulldown selected; 1=pullup selected
  [3] GPMC_A16_PULLUDENABLE rw — pullup/down enable for pad gpmc_a16
    0=pullup/down disabled; 1=pullup/down enabled
  [2:0] GPMC_A16_MUXMODE rw — Functional multiplexing selection for pad gpmc_a16
    0=Select gpmc_a16; 1=Select kpd_row4; 2=Select c2c_datain0; 3=Select gpio_40; 4=Select venc_656_data0; 7=Select safe_mode
0x64 CONTROL_CORE_PAD0_GPMC_A18_PAD1_GPMC_A19 — Register control for Pads gpmc_a18 and gpmc_a19 Access conditions. Read: unrestricted, Write: unrestricted
  [31] GPMC_A19_WAKEUPEVENT ro — Pad_x wake-up event status latched in the IO
    0=GPMC_A19_WAKEUPEVENT_0_r (No wake-up event occurred); 1=GPMC_A19_WAKEUPEVENT_1_r (A wake-up event occurred)
  [30] GPMC_A19_WAKEUPENABLE rw — Input pad wake-up enable (and OFF mode input enable value)
    values as CONTROL_CORE_PAD0_GPMC_AD0_PAD1_GPMC_AD1.GPMC_AD1_WAKEUPENABLE
  [29] GPMC_A19_OFFMODEPULLTYPESELECT rw — OffMode mode pullup/down selection for pad gpmc_a19
    0=Offmode pulldown selected; 1=Offmode pullup selected
  [28] GPMC_A19_OFFMODEPULLUDENABLE rw — OffMode mode pullup/down enable for pad gpmc_a19
    values as CONTROL_CORE_PAD0_GPMC_AD0_PAD1_GPMC_AD1.GPMC_AD1_OFFMODEPULLUDENABLE
  [27] GPMC_A19_OFFMODEOUTVALUE rw — OffMode mode output value for pad gpmc_a19
    0=Set value at 0; 1=Set value at 1
  [26] GPMC_A19_OFFMODEOUTENABLE rw — OffMode mode output enable value for pad gpmc_a19. This is an active low signal
    0=Output enable; 1=Output disable
  [25] GPMC_A19_OFFMODEENABLE rw — OffMode mode override control for pad gpmc_a19
    values as CONTROL_CORE_PAD0_GPMC_AD0_PAD1_GPMC_AD1.GPMC_AD1_OFFMODEENABLE
  [24] GPMC_A19_INPUTENABLE rw — Input enable value for pad gpmc_a19
    values as CONTROL_CORE_PAD0_GPMC_AD0_PAD1_GPMC_AD1.GPMC_AD1_INPUTENABLE
  [20] GPMC_A19_PULLTYPESELECT rw — pullup/down selection for pad gpmc_a19
    0=pulldown selected; 1=pullup selected
  [19] GPMC_A19_PULLUDENABLE rw — pullup/down enable for pad gpmc_a19
    0=pullup/down disabled; 1=pullup/down enabled
  [18:16] GPMC_A19_MUXMODE rw — Functional multiplexing selection for pad gpmc_a19
    0=Select gpmc_a19; 1=Select kpd_row7; 2=Select c2c_datain3; 3=Select gpio_43; 4=Select venc_656_data3; 7=Select safe_mode
  [15] GPMC_A18_WAKEUPEVENT ro — Pad_x wake-up event status latched in the IO
    0=GPMC_A18_WAKEUPEVENT_0_r (No wake-up event occurred); 1=GPMC_A18_WAKEUPEVENT_1_r (A wake-up event occurred)
  [14] GPMC_A18_WAKEUPENABLE rw — Input pad wake-up enable (and OFF mode input enable value)
    values as CONTROL_CORE_PAD0_GPMC_AD0_PAD1_GPMC_AD1.GPMC_AD1_WAKEUPENABLE
  [13] GPMC_A18_OFFMODEPULLTYPESELECT rw — OffMode mode pullup/down selection for pad gpmc_a18
    0=Offmode pulldown selected; 1=Offmode pullup selected
  [12] GPMC_A18_OFFMODEPULLUDENABLE rw — OffMode mode pullup/down enable for pad gpmc_a18
    values as CONTROL_CORE_PAD0_GPMC_AD0_PAD1_GPMC_AD1.GPMC_AD1_OFFMODEPULLUDENABLE
  [11] GPMC_A18_OFFMODEOUTVALUE rw — OffMode mode output value for pad gpmc_a18
    0=Set value at 0; 1=Set value at 1
  [10] GPMC_A18_OFFMODEOUTENABLE rw — OffMode mode output enable value for pad gpmc_a18. This is an active low signal
    0=Output enable; 1=Output disable
  [9] GPMC_A18_OFFMODEENABLE rw — OffMode mode override control for pad gpmc_a18
    values as CONTROL_CORE_PAD0_GPMC_AD0_PAD1_GPMC_AD1.GPMC_AD1_OFFMODEENABLE
  [8] GPMC_A18_INPUTENABLE rw — Input enable value for pad gpmc_a18
    values as CONTROL_CORE_PAD0_GPMC_AD0_PAD1_GPMC_AD1.GPMC_AD1_INPUTENABLE
  [4] GPMC_A18_PULLTYPESELECT rw — pullup/down selection for pad gpmc_a18
    0=pulldown selected; 1=pullup selected
  [3] GPMC_A18_PULLUDENABLE rw — pullup/down enable for pad gpmc_a18
    0=pullup/down disabled; 1=pullup/down enabled
  [2:0] GPMC_A18_MUXMODE rw — Functional multiplexing selection for pad gpmc_a18
    0=Select gpmc_a18; 1=Select kpd_row6; 2=Select c2c_datain2; 3=Select gpio_42; 4=Select venc_656_data2; 7=Select safe_mode
0x68 CONTROL_CORE_PAD0_GPMC_A20_PAD1_GPMC_A21 — Register control for Pads gpmc_a20 and gpmc_a21 Access conditions. Read: unrestricted, Write: unrestricted
  [31] GPMC_A21_WAKEUPEVENT ro — Pad_x wake-up event status latched in the IO
    0=GPMC_A21_WAKEUPEVENT_0_r (No wake-up event occurred); 1=GPMC_A21_WAKEUPEVENT_1_r (A wake-up event occurred)
  [30] GPMC_A21_WAKEUPENABLE rw — Input pad wake-up enable (and OFF mode input enable value)
    values as CONTROL_CORE_PAD0_GPMC_AD0_PAD1_GPMC_AD1.GPMC_AD1_WAKEUPENABLE
  [29] GPMC_A21_OFFMODEPULLTYPESELECT rw — OffMode mode pullup/down selection for pad gpmc_a21
    0=Offmode pulldown selected; 1=Offmode pullup selected
  [28] GPMC_A21_OFFMODEPULLUDENABLE rw — OffMode mode pullup/down enable for pad gpmc_a21
    values as CONTROL_CORE_PAD0_GPMC_AD0_PAD1_GPMC_AD1.GPMC_AD1_OFFMODEPULLUDENABLE
  [27] GPMC_A21_OFFMODEOUTVALUE rw — OffMode mode output value for pad gpmc_a21
    0=Set value at 0; 1=Set value at 1
  [26] GPMC_A21_OFFMODEOUTENABLE rw — OffMode mode output enable value for pad gpmc_a21. This is an active low signal
    0=Output enable; 1=Output disable
  [25] GPMC_A21_OFFMODEENABLE rw — OffMode mode override control for pad gpmc_a21
    values as CONTROL_CORE_PAD0_GPMC_AD0_PAD1_GPMC_AD1.GPMC_AD1_OFFMODEENABLE
  [24] GPMC_A21_INPUTENABLE rw — Input enable value for pad gpmc_a21
    values as CONTROL_CORE_PAD0_GPMC_AD0_PAD1_GPMC_AD1.GPMC_AD1_INPUTENABLE
  [20] GPMC_A21_PULLTYPESELECT rw — pullup/down selection for pad gpmc_a21
    0=pulldown selected; 1=pullup selected
  [19] GPMC_A21_PULLUDENABLE rw — pullup/down enable for pad gpmc_a21
    0=pullup/down disabled; 1=pullup/down enabled
  [18:16] GPMC_A21_MUXMODE rw — Functional multiplexing selection for pad gpmc_a21
    0=Select gpmc_a21; 1=Select kpd_col5; 2=Select c2c_datain5; 3=Select gpio_45; 4=Select venc_656_data5; 7=Select safe_mode
  [15] GPMC_A20_WAKEUPEVENT ro — Pad_x wake-up event status latched in the IO
    0=GPMC_A20_WAKEUPEVENT_0_r (No wake-up event occurred); 1=GPMC_A20_WAKEUPEVENT_1_r (A wake-up event occurred)
  [14] GPMC_A20_WAKEUPENABLE rw — Input pad wake-up enable (and OFF mode input enable value)
    values as CONTROL_CORE_PAD0_GPMC_AD0_PAD1_GPMC_AD1.GPMC_AD1_WAKEUPENABLE
  [13] GPMC_A20_OFFMODEPULLTYPESELECT rw — OffMode mode pullup/down selection for pad gpmc_a20
    0=Offmode pulldown selected; 1=Offmode pullup selected
  [12] GPMC_A20_OFFMODEPULLUDENABLE rw — OffMode mode pullup/down enable for pad gpmc_a20
    values as CONTROL_CORE_PAD0_GPMC_AD0_PAD1_GPMC_AD1.GPMC_AD1_OFFMODEPULLUDENABLE
  [11] GPMC_A20_OFFMODEOUTVALUE rw — OffMode mode output value for pad gpmc_a20
    0=Set value at 0; 1=Set value at 1
  [10] GPMC_A20_OFFMODEOUTENABLE rw — OffMode mode output enable value for pad gpmc_a20. This is an active low signal
    0=Output enable; 1=Output disable
  [9] GPMC_A20_OFFMODEENABLE rw — OffMode mode override control for pad gpmc_a20
    values as CONTROL_CORE_PAD0_GPMC_AD0_PAD1_GPMC_AD1.GPMC_AD1_OFFMODEENABLE
  [8] GPMC_A20_INPUTENABLE rw — Input enable value for pad gpmc_a20
    values as CONTROL_CORE_PAD0_GPMC_AD0_PAD1_GPMC_AD1.GPMC_AD1_INPUTENABLE
  [4] GPMC_A20_PULLTYPESELECT rw — pullup/down selection for pad gpmc_a20
    0=pulldown selected; 1=pullup selected
  [3] GPMC_A20_PULLUDENABLE rw — pullup/down enable for pad gpmc_a20
    0=pullup/down disabled; 1=pullup/down enabled
  [2:0] GPMC_A20_MUXMODE rw — Functional multiplexing selection for pad gpmc_a20
    0=Select gpmc_a20; 1=Select kpd_col4; 2=Select c2c_datain4; 3=Select gpio_44; 4=Select venc_656_data4; 7=Select safe_mode
0x6C CONTROL_CORE_PAD0_GPMC_A22_PAD1_GPMC_A23 — Register control for Pads gpmc_a22 and gpmc_a23 Access conditions. Read: unrestricted, Write: unrestricted
  [31] GPMC_A23_WAKEUPEVENT ro — Pad_x wake-up event status latched in the IO
    0=GPMC_A23_WAKEUPEVENT_0_r (No wake-up event occurred); 1=GPMC_A23_WAKEUPEVENT_1_r (A wake-up event occurred)
  [30] GPMC_A23_WAKEUPENABLE rw — Input pad wake-up enable (and OFF mode input enable value)
    values as CONTROL_CORE_PAD0_GPMC_AD0_PAD1_GPMC_AD1.GPMC_AD1_WAKEUPENABLE
  [29] GPMC_A23_OFFMODEPULLTYPESELECT rw — OffMode mode pullup/down selection for pad gpmc_a23
    0=Offmode pulldown selected; 1=Offmode pullup selected
  [28] GPMC_A23_OFFMODEPULLUDENABLE rw — OffMode mode pullup/down enable for pad gpmc_a23
    values as CONTROL_CORE_PAD0_GPMC_AD0_PAD1_GPMC_AD1.GPMC_AD1_OFFMODEPULLUDENABLE
  [27] GPMC_A23_OFFMODEOUTVALUE rw — OffMode mode output value for pad gpmc_a23
    0=Set value at 0; 1=Set value at 1
  [26] GPMC_A23_OFFMODEOUTENABLE rw — OffMode mode output enable value for pad gpmc_a23. This is an active low signal
    0=Output enable; 1=Output disable
  [25] GPMC_A23_OFFMODEENABLE rw — OffMode mode override control for pad gpmc_a23
    values as CONTROL_CORE_PAD0_GPMC_AD0_PAD1_GPMC_AD1.GPMC_AD1_OFFMODEENABLE
  [24] GPMC_A23_INPUTENABLE rw — Input enable value for pad gpmc_a23
    values as CONTROL_CORE_PAD0_GPMC_AD0_PAD1_GPMC_AD1.GPMC_AD1_INPUTENABLE
  [20] GPMC_A23_PULLTYPESELECT rw — pullup/down selection for pad gpmc_a23
    0=pulldown selected; 1=pullup selected
  [19] GPMC_A23_PULLUDENABLE rw — pullup/down enable for pad gpmc_a23
    0=pullup/down disabled; 1=pullup/down enabled
  [18:16] GPMC_A23_MUXMODE rw — Functional multiplexing selection for pad gpmc_a23
    0=Select gpmc_a23; 1=Select kpd_col7; 2=Select c2c_datain7; 3=Select gpio_47; 4=Select venc_656_data7; 7=Select safe_mode
  [15] GPMC_A22_WAKEUPEVENT ro — Pad_x wake-up event status latched in the IO
    0=GPMC_A22_WAKEUPEVENT_0_r (No wake-up event occurred); 1=GPMC_A22_WAKEUPEVENT_1_r (A wake-up event occurred)
  [14] GPMC_A22_WAKEUPENABLE rw — Input pad wake-up enable (and OFF mode input enable value)
    values as CONTROL_CORE_PAD0_GPMC_AD0_PAD1_GPMC_AD1.GPMC_AD1_WAKEUPENABLE
  [13] GPMC_A22_OFFMODEPULLTYPESELECT rw — OffMode mode pullup/down selection for pad gpmc_a22
    0=Offmode pulldown selected; 1=Offmode pullup selected
  [12] GPMC_A22_OFFMODEPULLUDENABLE rw — OffMode mode pullup/down enable for pad gpmc_a22
    values as CONTROL_CORE_PAD0_GPMC_AD0_PAD1_GPMC_AD1.GPMC_AD1_OFFMODEPULLUDENABLE
  [11] GPMC_A22_OFFMODEOUTVALUE rw — OffMode mode output value for pad gpmc_a22
    0=Set value at 0; 1=Set value at 1
  [10] GPMC_A22_OFFMODEOUTENABLE rw — OffMode mode output enable value for pad gpmc_a22. This is an active low signal
    0=Output enable; 1=Output disable
  [9] GPMC_A22_OFFMODEENABLE rw — OffMode mode override control for pad gpmc_a22
    values as CONTROL_CORE_PAD0_GPMC_AD0_PAD1_GPMC_AD1.GPMC_AD1_OFFMODEENABLE
  [8] GPMC_A22_INPUTENABLE rw — Input enable value for pad gpmc_a22
    values as CONTROL_CORE_PAD0_GPMC_AD0_PAD1_GPMC_AD1.GPMC_AD1_INPUTENABLE
  [4] GPMC_A22_PULLTYPESELECT rw — pullup/down selection for pad gpmc_a22
    0=pulldown selected; 1=pullup selected
  [3] GPMC_A22_PULLUDENABLE rw — pullup/down enable for pad gpmc_a22
    0=pullup/down disabled; 1=pullup/down enabled
  [2:0] GPMC_A22_MUXMODE rw — Functional multiplexing selection for pad gpmc_a22
    0=Select gpmc_a22; 1=Select kpd_col6; 2=Select c2c_datain6; 3=Select gpio_46; 4=Select venc_656_data6; 7=Select safe_mode
